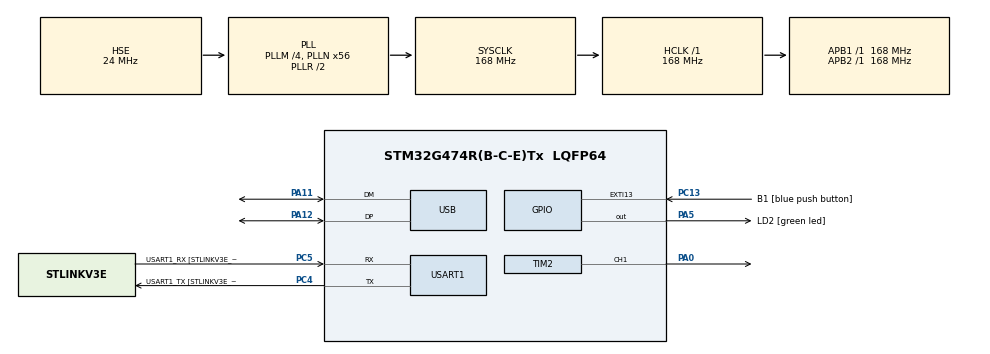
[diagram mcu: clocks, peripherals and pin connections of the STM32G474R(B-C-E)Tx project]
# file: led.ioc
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Mcu.Family=STM32G4
Mcu.Name=STM32G474R(B-C-E)Tx
Mcu.Package=LQFP64
NVIC.EXTI15_10_IRQn=true\:0\:0\:false\:false\:true\:true\:true
NVIC.PriorityGroup=NVIC_PRIORITYGROUP_4
NVIC.USB_LP_IRQn=true\:0\:0\:false\:false\:true\:false\:true
PA0.Signal=S_TIM2_CH1
PA11.Mode=Device
PA11.Signal=USB_DM
PA12.Mode=Device
PA12.Signal=USB_DP
PA13.GPIO_Label=T_SWDIO
PA13.Mode=Serial_Wire
PA13.Signal=SYS_JTMS-SWDIO
PA14.GPIO_Label=T_SWCLK
PA14.Mode=Serial_Wire
PA14.Signal=SYS_JTCK-SWCLK
PA5.GPIO_Label=LD2 [green led]
PA5.Signal=GPIO_Output
PB3.GPIO_Label=T_SWO
PB3.Signal=SYS_JTDO-SWO
PC13.GPIO_Label=B1 [blue push button]
PC13.Signal=GPXTI13
PC14-OSC32_IN.Mode=LSE-External-Oscillator
PC14-OSC32_IN.Signal=RCC_OSC32_IN
PC15-OSC32_OUT.Mode=LSE-External-Oscillator
PC15-OSC32_OUT.Signal=RCC_OSC32_OUT
PC4.GPIO_Label=USART1_TX [STLINKV3E_VCP_RX]
PC4.Mode=Asynchronous
PC4.Signal=USART1_TX
PC5.GPIO_Label=USART1_RX [STLINKV3E_VCP_TX]
PC5.Mode=Asynchronous
PC5.Signal=USART1_RX
PF0-OSC_IN.Mode=HSE-External-Oscillator
PF0-OSC_IN.Signal=RCC_OSC_IN
PF1-OSC_OUT.Mode=HSE-External-Oscillator
PF1-OSC_OUT.Signal=RCC_OSC_OUT
ProjectManager.HeapSize=0x200
ProjectManager.StackSize=0x400
ProjectManager.TargetToolchain=STM32CubeIDE
RCC.ADC12Freq_Value=168000000
RCC.ADC345Freq_Value=168000000
RCC.AHBFreq_Value=168000000
RCC.APB1Freq_Value=168000000
RCC.APB1TimFreq_Value=168000000
RCC.APB2Freq_Value=168000000
RCC.APB2TimFreq_Value=168000000
RCC.CK48CLockSelection=RCC_USBCLKSOURCE_HSI48
RCC.CortexFreq_Value=168000000
RCC.EXTERNAL_CLOCK_VALUE=12288000
RCC.HCLKFreq_Value=168000000
RCC.HSE_VALUE=24000000
RCC.HSI48_VALUE=48000000
RCC.HSI_VALUE=16000000
RCC.PLLM=RCC_PLLM_DIV4
RCC.PLLN=56
RCC.PLLSourceVirtual=RCC_PLLSOURCE_HSE
RCC.RTCClockSelection=RCC_RTCCLKSOURCE_LSE
RCC.SYSCLKFreq_VALUE=168000000
RCC.SYSCLKSource=RCC_SYSCLKSOURCE_PLLCLK
RCC.USBFreq_Value=48000000
RCC.VCOOutputFreq_Value=336000000
SH.S_TIM2_CH1.0=TIM2_CH1,PWM Generation1 CH1
TIM2.Channel-PWM\ Generation1\ CH1=TIM_CHANNEL_1
USART1.VirtualMode-Asynchronous=VM_ASYNC
USART1.WordLength=WORDLENGTH_8B
USB_DEVICE.CLASS_NAME_FS=CDC
USB_DEVICE.VirtualMode=Cdc
USB_DEVICE.VirtualModeFS=Cdc_FS
VP_SYS_VS_DBSignals.Mode=DisableDeadBatterySignals
VP_USB_DEVICE_VS_USB_DEVICE_CDC_FS.Mode=CDC_FS
board=NUCLEO-G474RE

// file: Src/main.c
/* USER CODE BEGIN Header */
/**
  ******************************************************************************
  * @file           : main.c
  * @brief          : Main program body
  ******************************************************************************
  * @attention
  *
  * <h2><center>&copy; Copyright (c) 2019 STMicroelectronics.
  * All rights reserved.</center></h2>
  *
  * This software component is licensed by ST under BSD 3-Clause license,
  * the "License"; You may not use this file except in compliance with the
  * License. You may obtain a copy of the License at:
  *                        opensource.org/licenses/BSD-3-Clause
  *
  ******************************************************************************
  */
/* USER CODE END Header */

#include "main.h"
#include "usb_device.h"

TIM_HandleTypeDef htim2;

UART_HandleTypeDef huart1;

void SystemClock_Config(void);
static void MX_GPIO_Init(void);
static void MX_USART1_UART_Init(void);
static void MX_TIM2_Init(void);

int main(void)
{

  /* MCU Configuration--------------------------------------------------------*/

  /* Reset of all peripherals, Initializes the Flash interface and the Systick. */
  HAL_Init();

  /* Configure the system clock */
  SystemClock_Config();

  /* Initialize all configured peripherals */
  MX_GPIO_Init();
  MX_USART1_UART_Init();
  MX_USB_Device_Init();
  MX_TIM2_Init();

  /* Infinite loop */
  while (1)
  {

    /* USER CODE BEGIN 3 */
	  if(HAL_GPIO_ReadPin(GPIOC, GPIO_PIN_13) == GPIO_PIN_SET){
		  HAL_GPIO_WritePin(GPIOA,GPIO_PIN_5,GPIO_PIN_SET);
		  CDC_Transmit_FS("hello\n", 6);
		  HAL_UART_Transmit_IT(  &huart1,"hello\n", 6);
	  }
	  else{
		  HAL_GPIO_WritePin(GPIOA,GPIO_PIN_5,GPIO_PIN_RESET);
	  }

  }
  /* USER CODE END 3 */
}

void SystemClock_Config(void)
{
  RCC_OscInitTypeDef RCC_OscInitStruct = {0};
  RCC_ClkInitTypeDef RCC_ClkInitStruct = {0};
  RCC_PeriphCLKInitTypeDef PeriphClkInit = {0};

  /** Configure the main internal regulator output voltage
  */
  HAL_PWREx_ControlVoltageScaling(PWR_REGULATOR_VOLTAGE_SCALE1_BOOST);
  /** Initializes the CPU, AHB and APB busses clocks
  */
  RCC_OscInitStruct.OscillatorType = RCC_OSCILLATORTYPE_HSI48|RCC_OSCILLATORTYPE_HSE;
  RCC_OscInitStruct.HSEState = RCC_HSE_ON;
  RCC_OscInitStruct.HSI48State = RCC_HSI48_ON;
  RCC_OscInitStruct.PLL.PLLState = RCC_PLL_ON;
  RCC_OscInitStruct.PLL.PLLSource = RCC_PLLSOURCE_HSE;
  RCC_OscInitStruct.PLL.PLLM = RCC_PLLM_DIV4;
  RCC_OscInitStruct.PLL.PLLN = 56;
  RCC_OscInitStruct.PLL.PLLP = RCC_PLLP_DIV2;
  RCC_OscInitStruct.PLL.PLLQ = RCC_PLLQ_DIV2;
  RCC_OscInitStruct.PLL.PLLR = RCC_PLLR_DIV2;
  if (HAL_RCC_OscConfig(&RCC_OscInitStruct) != HAL_OK)
  {
    Error_Handler();
  }
  /** Initializes the CPU, AHB and APB busses clocks
  */
  RCC_ClkInitStruct.ClockType = RCC_CLOCKTYPE_HCLK|RCC_CLOCKTYPE_SYSCLK
                              |RCC_CLOCKTYPE_PCLK1|RCC_CLOCKTYPE_PCLK2;
  RCC_ClkInitStruct.SYSCLKSource = RCC_SYSCLKSOURCE_PLLCLK;
  RCC_ClkInitStruct.AHBCLKDivider = RCC_SYSCLK_DIV1;
  RCC_ClkInitStruct.APB1CLKDivider = RCC_HCLK_DIV1;
  RCC_ClkInitStruct.APB2CLKDivider = RCC_HCLK_DIV1;

  if (HAL_RCC_ClockConfig(&RCC_ClkInitStruct, FLASH_LATENCY_8) != HAL_OK)
  {
    Error_Handler();
  }
  /** Initializes the peripherals clocks
  */
  PeriphClkInit.PeriphClockSelection = RCC_PERIPHCLK_USART1|RCC_PERIPHCLK_USB;
  PeriphClkInit.Usart1ClockSelection = RCC_USART1CLKSOURCE_PCLK2;
  PeriphClkInit.UsbClockSelection = RCC_USBCLKSOURCE_HSI48;
  if (HAL_RCCEx_PeriphCLKConfig(&PeriphClkInit) != HAL_OK)
  {
    Error_Handler();
  }
}

static void MX_TIM2_Init(void)
{

  TIM_MasterConfigTypeDef sMasterConfig = {0};
  TIM_OC_InitTypeDef sConfigOC = {0};

  htim2.Instance = TIM2;
  htim2.Init.Prescaler = 0;
  htim2.Init.CounterMode = TIM_COUNTERMODE_UP;
  htim2.Init.Period = 0;
  htim2.Init.ClockDivision = TIM_CLOCKDIVISION_DIV1;
  htim2.Init.AutoReloadPreload = TIM_AUTORELOAD_PRELOAD_DISABLE;
  if (HAL_TIM_PWM_Init(&htim2) != HAL_OK)
  {
    Error_Handler();
  }
  sMasterConfig.MasterOutputTrigger = TIM_TRGO_RESET;
  sMasterConfig.MasterSlaveMode = TIM_MASTERSLAVEMODE_DISABLE;
  if (HAL_TIMEx_MasterConfigSynchronization(&htim2, &sMasterConfig) != HAL_OK)
  {
    Error_Handler();
  }
  sConfigOC.OCMode = TIM_OCMODE_PWM1;
  sConfigOC.Pulse = 0;
  sConfigOC.OCPolarity = TIM_OCPOLARITY_HIGH;
  sConfigOC.OCFastMode = TIM_OCFAST_DISABLE;
  if (HAL_TIM_PWM_ConfigChannel(&htim2, &sConfigOC, TIM_CHANNEL_1) != HAL_OK)
  {
    Error_Handler();
  }
  HAL_TIM_MspPostInit(&htim2);

}

static void MX_USART1_UART_Init(void)
{

  huart1.Instance = USART1;
  huart1.Init.BaudRate = 115200;
  huart1.Init.WordLength = UART_WORDLENGTH_8B;
  huart1.Init.StopBits = UART_STOPBITS_1;
  huart1.Init.Parity = UART_PARITY_NONE;
  huart1.Init.Mode = UART_MODE_TX_RX;
  huart1.Init.HwFlowCtl = UART_HWCONTROL_NONE;
  huart1.Init.OverSampling = UART_OVERSAMPLING_16;
  huart1.Init.OneBitSampling = UART_ONE_BIT_SAMPLE_DISABLE;
  huart1.Init.ClockPrescaler = UART_PRESCALER_DIV1;
  huart1.AdvancedInit.AdvFeatureInit = UART_ADVFEATURE_NO_INIT;
  if (HAL_UART_Init(&huart1) != HAL_OK)
  {
    Error_Handler();
  }
  if (HAL_UARTEx_SetTxFifoThreshold(&huart1, UART_TXFIFO_THRESHOLD_1_8) != HAL_OK)
  {
    Error_Handler();
  }
  if (HAL_UARTEx_SetRxFifoThreshold(&huart1, UART_RXFIFO_THRESHOLD_1_8) != HAL_OK)
  {
    Error_Handler();
  }
  if (HAL_UARTEx_DisableFifoMode(&huart1) != HAL_OK)
  {
    Error_Handler();
  }

}

static void MX_GPIO_Init(void)
{
  GPIO_InitTypeDef GPIO_InitStruct = {0};

  /* GPIO Ports Clock Enable */
  __HAL_RCC_GPIOC_CLK_ENABLE();
  __HAL_RCC_GPIOF_CLK_ENABLE();
  __HAL_RCC_GPIOG_CLK_ENABLE();
  __HAL_RCC_GPIOA_CLK_ENABLE();
  __HAL_RCC_GPIOB_CLK_ENABLE();
  __HAL_RCC_GPIOD_CLK_ENABLE();

  /*Configure GPIO pin Output Level */
  HAL_GPIO_WritePin(LD2_GPIO_Port, LD2_Pin, GPIO_PIN_RESET);

  /*Configure GPIO pin : B1_Pin */
  GPIO_InitStruct.Pin = B1_Pin;
  GPIO_InitStruct.Mode = GPIO_MODE_IT_RISING;
  GPIO_InitStruct.Pull = GPIO_NOPULL;
  HAL_GPIO_Init(B1_GPIO_Port, &GPIO_InitStruct);

  /*Configure GPIO pin : PG10 */
  GPIO_InitStruct.Pin = GPIO_PIN_10;
  GPIO_InitStruct.Mode = GPIO_MODE_ANALOG;
  GPIO_InitStruct.Pull = GPIO_NOPULL;
  HAL_GPIO_Init(GPIOG, &GPIO_InitStruct);

  /*Configure GPIO pins : PC0 PC1 PC2 PC3
                           PC6 PC7 PC8 PC9
                           PC10 PC11 PC12 */
  GPIO_InitStruct.Pin = GPIO_PIN_0|GPIO_PIN_1|GPIO_PIN_2|GPIO_PIN_3
                          |GPIO_PIN_6|GPIO_PIN_7|GPIO_PIN_8|GPIO_PIN_9
                          |GPIO_PIN_10|GPIO_PIN_11|GPIO_PIN_12;
  GPIO_InitStruct.Mode = GPIO_MODE_ANALOG;
  GPIO_InitStruct.Pull = GPIO_NOPULL;
  HAL_GPIO_Init(GPIOC, &GPIO_InitStruct);

  /*Configure GPIO pins : PA1 PA2 PA3 PA4
                           PA6 PA7 PA8 PA9
                           PA10 PA15 */
  GPIO_InitStruct.Pin = GPIO_PIN_1|GPIO_PIN_2|GPIO_PIN_3|GPIO_PIN_4
                          |GPIO_PIN_6|GPIO_PIN_7|GPIO_PIN_8|GPIO_PIN_9
                          |GPIO_PIN_10|GPIO_PIN_15;
  GPIO_InitStruct.Mode = GPIO_MODE_ANALOG;
  GPIO_InitStruct.Pull = GPIO_NOPULL;
  HAL_GPIO_Init(GPIOA, &GPIO_InitStruct);

  /*Configure GPIO pin : LD2_Pin */
  GPIO_InitStruct.Pin = LD2_Pin;
  GPIO_InitStruct.Mode = GPIO_MODE_OUTPUT_PP;
  GPIO_InitStruct.Pull = GPIO_NOPULL;
  GPIO_InitStruct.Speed = GPIO_SPEED_FREQ_LOW;
  HAL_GPIO_Init(LD2_GPIO_Port, &GPIO_InitStruct);

  /*Configure GPIO pins : PB0 PB1 PB2 PB10
                           PB11 PB12 PB13 PB14
                           PB15 PB4 PB5 PB6
                           PB7 PB8 PB9 */
  GPIO_InitStruct.Pin = GPIO_PIN_0|GPIO_PIN_1|GPIO_PIN_2|GPIO_PIN_10
                          |GPIO_PIN_11|GPIO_PIN_12|GPIO_PIN_13|GPIO_PIN_14
                          |GPIO_PIN_15|GPIO_PIN_4|GPIO_PIN_5|GPIO_PIN_6
                          |GPIO_PIN_7|GPIO_PIN_8|GPIO_PIN_9;
  GPIO_InitStruct.Mode = GPIO_MODE_ANALOG;
  GPIO_InitStruct.Pull = GPIO_NOPULL;
  HAL_GPIO_Init(GPIOB, &GPIO_InitStruct);

  /*Configure GPIO pin : PD2 */
  GPIO_InitStruct.Pin = GPIO_PIN_2;
  GPIO_InitStruct.Mode = GPIO_MODE_ANALOG;
  GPIO_InitStruct.Pull = GPIO_NOPULL;
  HAL_GPIO_Init(GPIOD, &GPIO_InitStruct);

  /* EXTI interrupt init*/
  HAL_NVIC_SetPriority(EXTI15_10_IRQn, 0, 0);
  HAL_NVIC_EnableIRQ(EXTI15_10_IRQn);

}

void Error_Handler(void)
{
}

/************************ (C) COPYRIGHT STMicroelectronics *****END OF FILE****/
